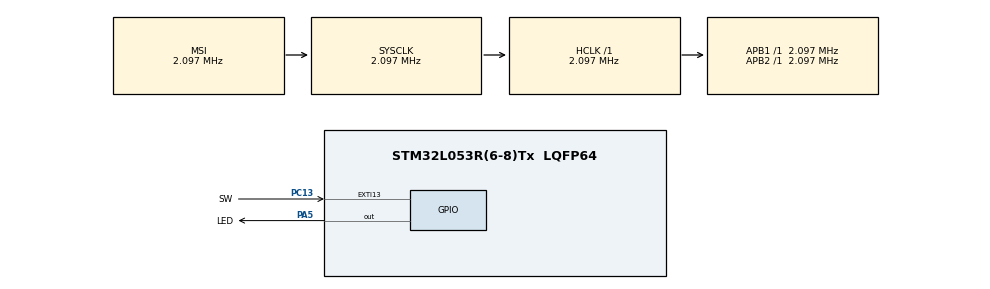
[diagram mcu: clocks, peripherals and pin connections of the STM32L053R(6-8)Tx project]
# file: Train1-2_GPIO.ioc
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Mcu.Family=STM32L0
Mcu.Name=STM32L053R(6-8)Tx
Mcu.Package=LQFP64
PA5.GPIO_Label=LED
PA5.GPIO_ModeDefaultOutputPP=GPIO_MODE_OUTPUT_PP
PA5.GPIO_PuPd=GPIO_PULLDOWN
PA5.PinState=GPIO_PIN_RESET
PA5.Signal=GPIO_Output
PC13.GPIO_Label=SW
PC13.GPIO_PuPd=GPIO_NOPULL
PC13.Signal=GPXTI13
ProjectManager.HeapSize=0x200
ProjectManager.StackSize=0x400
ProjectManager.TargetToolchain=STM32CubeIDE
RCC.AHBFreq_Value=2097000
RCC.APB1Freq_Value=2097000
RCC.APB1TimFreq_Value=2097000
RCC.APB2Freq_Value=2097000
RCC.APB2TimFreq_Value=2097000
RCC.HSE_VALUE=8000000
RCC.HSI16_VALUE=16000000
RCC.HSI48_VALUE=48000000
RCC.HSI_VALUE=16000000
RCC.LSE_VALUE=32768
RCC.MSI_VALUE=2097000
RCC.SYSCLKFreq_VALUE=2097000
RCC.VCOOutputFreq_Value=48000000
VP_TIM6_VS_ClockSourceINT.Mode=Enable_Timer
board=custom

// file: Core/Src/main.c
/* USER CODE BEGIN Header */
/**
 ******************************************************************************
 * @file           : main.c
 * @brief          : Main program body
 ******************************************************************************
 * @attention
 *
 * <h2><center>&copy; Copyright (c) 2020 STMicroelectronics.
 * All rights reserved.</center></h2>
 *
 * This software component is licensed by ST under BSD 3-Clause license,
 * the "License"; You may not use this file except in compliance with the
 * License. You may obtain a copy of the License at:
 *                        opensource.org/licenses/BSD-3-Clause
 *
 ******************************************************************************
 */
/* USER CODE END Header */
#include "main.h"

TIM_HandleTypeDef htim6;

void SystemClock_Config(void);
static void MX_GPIO_Init(void);
static void MX_TIM6_Init(void);

int main(void) {
	/* USER CODE BEGIN 1 */

	GPIO_PinState l_SWState;

	/* USER CODE END 1 */

	/* MCU Configuration--------------------------------------------------------*/

	/* Reset of all peripherals, Initializes the Flash interface and the Systick. */
	HAL_Init();

	/* Configure the system clock */
	SystemClock_Config();

	/* Initialize all configured peripherals */
	MX_GPIO_Init();
	MX_TIM6_Init();

	/* Infinite loop */
	while (1) {

		/* USER CODE BEGIN 3 */

		// メインループ内で、SWの値をリードし、
		// SWの値に合わせてLEDの状態を切り替える、
		l_SWState = HAL_GPIO_ReadPin(SW_GPIO_Port, SW_Pin);
		HAL_GPIO_WritePin(LED_GPIO_Port, LED_Pin, l_SWState);

	}
	/* USER CODE END 3 */
}

void SystemClock_Config(void) {
	RCC_OscInitTypeDef RCC_OscInitStruct = { 0 };
	RCC_ClkInitTypeDef RCC_ClkInitStruct = { 0 };

	/** Configure the main internal regulator output voltage
	 */
	__HAL_PWR_VOLTAGESCALING_CONFIG(PWR_REGULATOR_VOLTAGE_SCALE1);
	/** Initializes the RCC Oscillators according to the specified parameters
	 * in the RCC_OscInitTypeDef structure.
	 */
	RCC_OscInitStruct.OscillatorType = RCC_OSCILLATORTYPE_MSI;
	RCC_OscInitStruct.MSIState = RCC_MSI_ON;
	RCC_OscInitStruct.MSICalibrationValue = 0;
	RCC_OscInitStruct.MSIClockRange = RCC_MSIRANGE_5;
	RCC_OscInitStruct.PLL.PLLState = RCC_PLL_NONE;
	if (HAL_RCC_OscConfig(&RCC_OscInitStruct) != HAL_OK) {
		Error_Handler();
	}
	/** Initializes the CPU, AHB and APB buses clocks
	 */
	RCC_ClkInitStruct.ClockType = RCC_CLOCKTYPE_HCLK | RCC_CLOCKTYPE_SYSCLK
			| RCC_CLOCKTYPE_PCLK1 | RCC_CLOCKTYPE_PCLK2;
	RCC_ClkInitStruct.SYSCLKSource = RCC_SYSCLKSOURCE_MSI;
	RCC_ClkInitStruct.AHBCLKDivider = RCC_SYSCLK_DIV1;
	RCC_ClkInitStruct.APB1CLKDivider = RCC_HCLK_DIV1;
	RCC_ClkInitStruct.APB2CLKDivider = RCC_HCLK_DIV1;

	if (HAL_RCC_ClockConfig(&RCC_ClkInitStruct, FLASH_LATENCY_0) != HAL_OK) {
		Error_Handler();
	}
}

static void MX_TIM6_Init(void) {

	TIM_MasterConfigTypeDef sMasterConfig = { 0 };

	htim6.Instance = TIM6;
	htim6.Init.Prescaler = 0;
	htim6.Init.CounterMode = TIM_COUNTERMODE_UP;
	htim6.Init.Period = 65535;
	htim6.Init.AutoReloadPreload = TIM_AUTORELOAD_PRELOAD_DISABLE;
	if (HAL_TIM_Base_Init(&htim6) != HAL_OK) {
		Error_Handler();
	}
	sMasterConfig.MasterOutputTrigger = TIM_TRGO_RESET;
	sMasterConfig.MasterSlaveMode = TIM_MASTERSLAVEMODE_DISABLE;
	if (HAL_TIMEx_MasterConfigSynchronization(&htim6, &sMasterConfig)
			!= HAL_OK) {
		Error_Handler();
	}

}

static void MX_GPIO_Init(void) {
	GPIO_InitTypeDef GPIO_InitStruct = { 0 };

	/* GPIO Ports Clock Enable */
	__HAL_RCC_GPIOC_CLK_ENABLE();
	__HAL_RCC_GPIOA_CLK_ENABLE();

	/*Configure GPIO pin Output Level */
	HAL_GPIO_WritePin(LED_GPIO_Port, LED_Pin, GPIO_PIN_RESET);

	/*Configure GPIO pin : SW_Pin */
	GPIO_InitStruct.Pin = SW_Pin;
	GPIO_InitStruct.Mode = GPIO_MODE_IT_RISING;
	GPIO_InitStruct.Pull = GPIO_NOPULL;
	HAL_GPIO_Init(SW_GPIO_Port, &GPIO_InitStruct);

	/*Configure GPIO pin : LED_Pin */
	GPIO_InitStruct.Pin = LED_Pin;
	GPIO_InitStruct.Mode = GPIO_MODE_OUTPUT_PP;
	GPIO_InitStruct.Pull = GPIO_PULLDOWN;
	GPIO_InitStruct.Speed = GPIO_SPEED_FREQ_LOW;
	HAL_GPIO_Init(LED_GPIO_Port, &GPIO_InitStruct);

}

void Error_Handler(void) {
}

/************************ (C) COPYRIGHT STMicroelectronics *****END OF FILE****/
